# dm64lc_cslr_uart register map
Vendor: Texas Instruments
Peripheral module from a debugger description file.
Registers are 32-bit, access not given, reset 0x0 unless marked. A register's access mark holds for its fields unless they carry their own. Offsets are as the file gives them; lines under a group give offsets from that group; [hi:lo] are bit positions; {n}, {i} and the like mark numbered series; 'fields as' and 'values as' point back to an identical list; <NAME> marks a mode.

## UART — Universal Asynchronous Receive Transmit
0x00 RBR — Receiver Buffer Register
  [7:0] DATA ro — Received data
0x00 THR — Transmitter Holding Register
  [7:0] DATA wo — Data to transmit
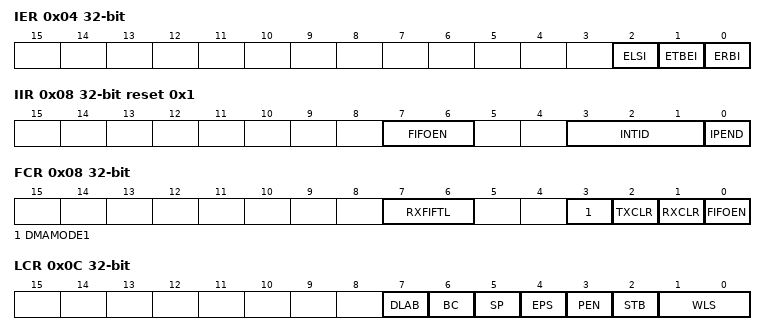
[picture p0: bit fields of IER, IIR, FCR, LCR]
0x04 IER — Interrupt Enable Register
  [all] fields
    0=DISABLE; 1=ENABLE
  [2] ELSI rw — Enable Receiver Line Status Interrupt
  [1] ETBEI rw — Enable Transmitter Holding Register Empty Interrupt
  [0] ERBI rw — Enable Receiver Data Available Interrupt and Character Timeout indication Interrupt
0x08 IIR reset 0x1 — Interrupt Identification Register
  [7:6] FIFOEN ro — FIFOs Enabled Always 00b in Non-FIFO mode Set to 11b when bit 0 of the FCR register is set
  [3:1] INTID ro — Encodes the different types of interrupt
    0=MODSTAT (Modem Status (Priority 4) Lowest); 1=THRE (THR Empty (Priority 3)); 2=RDA (Received Data Available (Priority 2)); 3=RLS (Receiver Line Status (Priority 1) Highest); 6=CTI (Character Timeout Indication (Priority 2))
  [0] IPEND ro — Interrupt Pending This bit is used either in a hardwire prioritized (nirq) or polled interrupt system
    1=NONE (No interrupts pending)
0x08 FCR — FIFO Control Register
  [7:6] RXFIFTL wo — Receiver FIFO Trigger Level (In bytes)
    0=CHAR1 (1 byte); 1=CHAR4 (4 byte); 2=CHAR8 (8 byte); 3=CHAR14 (14 byte)
  [3] DMAMODE1 wo — DMA MODE1 enable if FIFOs are enabled. Always write 1 to DMAMODE1. After a hardware reset, change DMAMODE1 from 0 to 1. DMAMOD1 = 1 is a requirement for proper communication between the UART and the EDMA controller
    0=DISABLE (Disable DMA); 1=ENABLE (Enables MODE1)
  [2] TXCLR wo — Setting this bit clears the transmitter FIFO and resets the transmitter FIFO counter. The shift register is not cleared. The 1 that is written to this bit position is self-clearing
    1=CLR (Clears Tx FIFO)
  [1] RXCLR wo — Setting this bit resets the receiver FIFO counter. The shift register is not cleared. The 1 that is written to this bit position is self-clearing
    1=CLR (Clears Rx FIFO)
  [0] FIFOEN wo — Setting this bit enables the transmitter and receiver FIFOs. This bit must be set when other FCR bits are written to or they are not programmed. Clearing this bit clears the FIFO counters
    0=DISABLE (Disable FIFOs); 1=ENABLE (Enable FIFOs)
0x0C LCR — Line Control Register
  [7] DLAB rw — Divisor Latch Access Bit This bit must be set to access the divisor latches of the baud generator during a read or write operation This bit must be cleared to access the receiver buffer register, the transmitter holding register, or the interrupt enable register
  [6] BC rw — Break Control Bit
    0=DISABLE (Break condition is disabled); 1=ENABLE (Break condition is transmitted to the receiving UART)
  [5] SP rw — Stick Parity Bit When this bit is set and even parity is selected, the parity bit is transmitted and checked as cleared When this bit is set and odd parity is selected, the parity bit is transmitted and checked as set When this bit is cleared, stick parity is disabled
  [4] EPS rw — Even Parity Select When this bit is set and parity is enabled, even parity is selected (an even number of logic 1s is transmitted or checked in the data and parity bits) When this bit is cleared and parity is enabled, odd parity is selected (an odd number of logic 1s is transmitted or checked)
  [3] PEN rw — Parity Enable 0: no parity bit is transmitted or checked 1: a parity bit is generated in transmitted data and is checked in received data between the last data word bit and the first stop bit
  [2] STB rw — Number of Stop Bits Generated This bit specifies either one, one and a half, or two stop bits in each transmitted character. This bit is combined with the word length bits (LCR[1] and LCR[0]) determine the number of stop bits. The receiver clocks only the first stop bit regardless of the number of stop bits selected -------------------------------------------------------------------------------------------- Bit 2 Word Length Number of Stop Bits Generated -------------------------------------------------------------------------------------------- 0 Any word length 1 1 5 bits 1.5 1 6 bits 2 1 7 bits 2 1 8 bits 2
  [1:0] WLS rw — Word Length Select Number of bits in each transmitted or received serial character
    {v}=BITS{v+5} ({v+5} bits) (v=0..3)
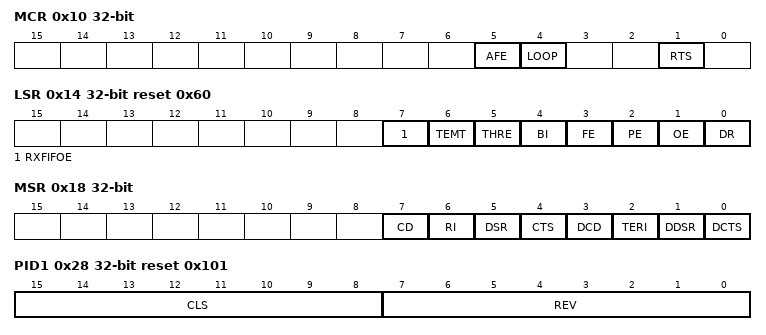
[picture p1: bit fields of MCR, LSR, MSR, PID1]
0x10 MCR — Modem Control Register
  [5] AFE rw — Autoflow control enable. Autoflow control allows the RTS and CTS signals to provide handshaking between UARTs during data transfer. When AFE = 1, the RTS bit determines the autoflow control enabled. ---------------------------------------------------------------------- Bit 5 Bit 1 Autoflow Control Configuration ---------------------------------------------------------------------- 1 1 Auto-rts and auto-cts enabled 1 0 Auto-cts only enabled 0 X Auto-rts and auto-cts disabled
    0=DISABLE (Autoflow control is disabled); 1=ENABLE (Autoflow control is enabled)
  [4] LOOP rw — Loop back mode enable. LOOP is used for the diagnostic testing using the loop back feature
    0=DISABLE (Disable loop back mode); 1=ENABLE (Enable loop back mode)
  [1] RTS rw — RTS control bit. When AFE = 1, the RTS bit determines the autoflow control enabled.
    0=HIGH (The associated output is forced high); 0=DISABLE (Auto-rts is disabled); 1=ENABLE (Auto-rts is enabled); 1=LOW (The associated output is forced low)
0x14 LSR reset 0x60 — Line Status Register
  [7] RXFIFOE ro — Receiver FIFO error. In non-FIFO mode: 0. There has been no error, or RXFIFOE was cleared because the CPU read the erroneous character from the receiver buffer register (RBR). 1. There is a parity error, framing error, or break indicator in the receiver buffer register (RBR). In FIFO mode: 0. There has been no error, or RXFIFOE was cleared because the CPU read the erroneous character from the receiver FIFO and there are no more errors in the receiver FIFO. 1. At least one parity error, framing error, or break indicator in the receiver FIFO.
  [6] TEMT ro — Transmitter empty (TEMT) indicator. In non-FIFO mode: 0. Either the transmitter holding register (THR) or the transmitter shift register (TSR) contains a data character. 1. Both the transmitter holding register (THR) and the transmitter shift register (TSR) are empty. In FIFO mode: 0. Either the transmitter FIFO or the transmitter shift register (TSR) contains a data character. 1. Both the transmitter FIFO and the transmitter shift register (TSR) are empty.
  [5] THRE ro — Transmitter holding register empty (THRE) indicator. If the THRE bit is set and the corresponding interrupt enable bit is set (ETBEI = 1 in IER), an interrupt request is generated. In non-FIFO mode: 0. Transmitter holding register (THR) is not empty. THR has been loaded by the CPU. 1. Transmitter holding register (THR) is empty (ready to accept a new character). The content of THR has been transferred to the transmitter shift register (TSR). In FIFO mode: 0. Transmitter FIFO is not empty. At least one character has been written to the transmitter FIFO. You can write to the transmitter FIFO if it is not full. 1. Transmitter FIFO is empty. The last character in the FIFO has been transferred to the transmitter shift register (TSR).
  [4] BI ro — Break indicator. The BI bit is set whenever the receive data input (RX) was held low for longer than a full-word transmission time. A full-word transmission time is defined as the total time to transmit the START, data, PARITY, and STOP bits. If the BI bit is set and the corresponding interrupt enable bit is set (ELSI = 1 in IER), an interrupt request is generated. In non-FIFO mode: 0. No break has been detected, or the BI bit was cleared because the CPU read the erroneous character from the receiver buffer register (RBR). 1. A break has been detected with the character in the receiver buffer register (RBR). In FIFO mode: 0. No break has been detected, or the BI bit was cleared because the CPU read the erroneous character from the receiver FIFO and the next character to be read from the FIFO has no break indicator. 1. A break has been detected with the character at the top of the receiver FIFO.
  [3] FE ro — Framing error (FE) indicator. A framing error occurs when the received character does not have a valid STOP bit. In response to a framing error, the UART sets the FE bit and waits until the signal on the RX pin goes high. Once the RX signal goes high, the receiver is ready to detect a new START bit and receive new data. If the FE bit is set and the corresponding interrupt enable bit is set (ELSI = 1 in IER), an interrupt request is generated. In non-FIFO mode: 0. No framing error has been detected, or the FE bit was cleared because the CPU read the erroneous data from the receiver buffer register (RBR). 1. A framing error has been detected with the character in the receiver buffer register (RBR). In FIFO mode: 0. No framing error has been detected, or the FE bit was cleared because the CPU read the erroneous data from the receiver FIFO and the next character to be read from the FIFO has no framing error. 1. A framing error has been detected with the character at the top of the receiver FIFO.
  [2] PE ro — Parity error (PE) indicator. A parity error occurs when the parity of the received character does not match the parity selected with the EPS bit in the line control register (LCR). If the PE bit is set and the corresponding interrupt enable bit is set (ELSI = 1 in IER), an interrupt request is generated. In non-FIFO mode: 0. No parity error has been detected, or the PE bit was cleared because the CPU read the erroneous data from the receiver buffer register (RBR). 1. A parity error has been detected with the character in the receiver buffer register (RBR). In FIFO mode: 0. No parity error has been detected, or the PE bit was cleared because the CPU read the erroneous data from the receiver FIFO and the next character to be read from the FIFO has no parity error. 1. A parity error has been detected with the character at the top of the receiver FIFO.
  [1] OE ro — Overrun error (OE) indicator An overrun error in the non-FIFO mode is different from an overrun error in the FIFO mode. If the OE bit is set and the corresponding interrupt enable bit is set (ELSI = 1 in IER), an interrupt request is generated. In non-FIFO mode: 0. No overrun error has been detected, or the OE bit was cleared because the CPU read the content of the line status register (LSR). 1. Overrun error has been detected. Before the character in the receiver buffer register (RBR) could be read, it was overwritten by the next character arriving in RBR. In FIFO mode: 0. No overrun error has been detected, or the OE bit was cleared because the CPU read the content of the line status register (LSR). 1. Overrun error has been detected. If data continues to fill the FIFO beyond the trigger level, an overrun error occurs only after the FIFO is full and the next character has been completely received in the shift register. An overrun error is indicated to the CPU as soon as it happens. The new character overwrites the character in the shift register, but it is not transferred to the FIFO.
  [0] DR ro — Data-ready (DR) indicator for the receiver. If the DR bit is set and the corresponding interrupt enable bit is set (ERBI = 1 in IER), an interrupt request is generated. In non-FIFO mode: 0. Data is not ready, or the DR bit was cleared because the character was read from the receiver buffer register (RBR). 1. Data is ready. A complete incoming character has been received and transferred into the receiver buffer register (RBR). In FIFO mode: 0. Data is not ready, or the DR bit was cleared because all of the characters in the receiver FIFO have been read. 1. Data is ready. There is at least one unread character in the receiver FIFO. If the FIFO is empty, the DR bit is set as soon as a complete incoming character has been received and transferred into the FIFO. The DR bit remains set until the FIFO is empty again.
0x18 MSR — Modem Status Register
  [7] CD ro — Complement of the Carrier Detect input When the UART is in the diagnostic test mode (loopback mode MCR[4] = 1), this bit is equal to the MCR bit 3 (OUT2)
  [6] RI ro — Complement of the Ring Indicator input When the UART is in the diagnostic test mode (loopback mode MCR[4] = 1), this bit is equal to the MCR bit 2 (OUT1)
  [5] DSR ro — Complement of the Data Set Ready input When the UART is in the diagnostic test mode (loopback mode MCR[4] = 1), this bit is equal to the MCR bit 0 (DTR)
  [4] CTS ro — Complement of the Clear To Send input When the UART is in the diagnostic test mode (loopback mode MCR[4] = 1), this bit is equal to the MCR bit 1 (RTS)
  [3] DCD ro — Change in DCD indicator bit DCD indicates that the DCD input has changed state since the last time it was read by the CPU. When DCD is set and the modem status interrupt is enabled, a modem status interrupt is generated
  [2] TERI ro — Trailing edge of RI (TERI) indicator bit TERI indicates that the RI input has changed from a low to a high. When TERI is set and the modem status interrupt is enabled, a modem status interrupt is generated
  [1] DDSR ro — Change in DSR indicator bit DDSR indicates that the DSR input has changed state since the last time it was read by the CPU. When DDSR is set and the modem status interrupt is enabled, a modem status interrupt is generated
  [0] DCTS ro — Change in CTS indicator bit DCTS indicates that the CTS input has changed state since the last time it was read by the CPU. When DCTS is set (autoflow control is not enabled and the modem status interrupt is enabled), a modem status interrupt is generated. When autoflow control is enabled, no interrupt is generated
0x20 DLL — Divisor Latch (LSB)
  [7:0] DLL rw — The 8 least-significant bits (LSBs) of the 16-bit divisor for generation of the baud clock in the baud rate generator
0x24 DLH — Divisor Latch (MSB)
  [7:0] DLH rw — The 8 most-significant bits (MSBs) of the 16-bit divisor for generation of the baud clock in the baud rate generator
0x28 PID1 reset 0x101 — Peripheral ID Register 1 (Class/Revision)
  [15:8] CLS ro — Class of Peripheral
  [7:0] REV ro — Revision level of the UART
0x2C PID2 reset 0x4 — Peripheral ID Register 2 (Type)
  [7:0] TYP ro — Type of peripheral
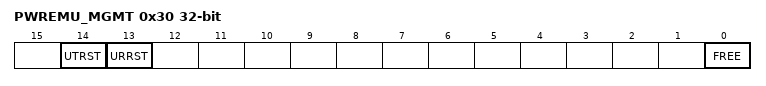
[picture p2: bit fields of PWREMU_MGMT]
0x30 PWREMU_MGMT — Power Management and Emulation Register
  [14] UTRST rw — UART transmitter reset. Resets and enables the transmitter
    0=RESET (Transmitter is disabled and in reset state); 1=ENABLE (Transmitter is enabled)
  [13] URRST rw — UART receiver reset. Resets and enables the receiver
    0=RESET (Receiver is disabled and in reset state); 1=ENABLE (Receiver is enabled)
  [0] FREE rw — Free-running enable mode bit. This bit determines the emulation mode functionality of the UART. In suspended mode, the UART can handle register read/write requests, but does not generate any transmission/reception, interrupts or events.
    0=STOP (If a transmission is not in progress, the UART stops immediately. If a transmission is in progress, the UART stops after completion of the one word transmission); 1=RUN (Free-running mode is enabled; UART continues to run normally)
